# rCSL_dmaxpdsp_001 register map
Vendor: Texas Instruments
Peripheral module from a debugger description file (folder c674x).
Registers are 32-bit, access not given, reset 0x0 unless marked. A register's access mark holds for its fields unless they carry their own. Offsets are as the file gives them; lines under a group give offsets from that group; [hi:lo] are bit positions; {n}, {i} and the like mark numbered series; 'fields as' and 'values as' point back to an identical list; <NAME> marks a mode.

## dMAXPDSP — dMAX Packed Data Structure Processor
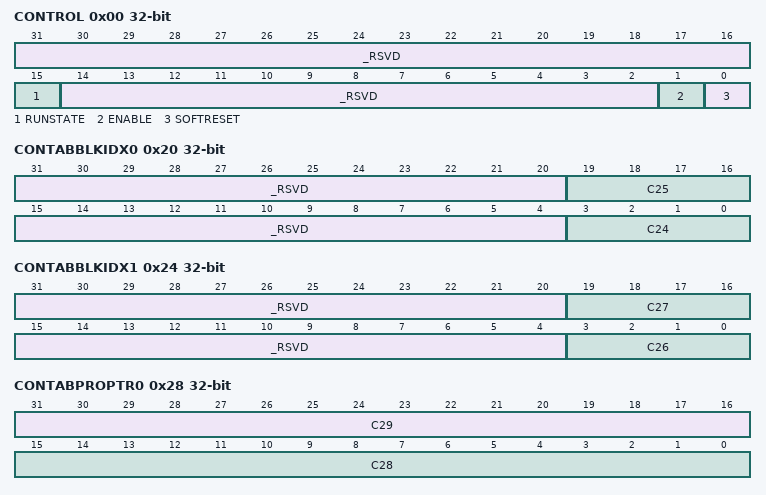
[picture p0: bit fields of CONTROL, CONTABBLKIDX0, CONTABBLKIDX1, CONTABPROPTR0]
0x00 CONTROL
  [31:16] _RSVD — (access N)
  [15] RUNSTATE ro
    0=HALT; 1=RUN
  [14:2] _RSVD — (access N)
  [1] ENABLE rw
    0=DISABLE; 1=ENABLE
  [0] SOFTRESET ro
    0=RESET; 1=OUT_OF_RESET
0x20 CONTABBLKIDX0 — Constant Table Block Index Register 0
  [31:20] _RSVD — (access N)
  [19:16] C25 rw — Constant Table Entry 25 Block Index
  [15:4] _RSVD — (access N)
  [3:0] C24 rw — Constant Table Entry 24 Block Index
0x24 CONTABBLKIDX1 — Constant Table Block Index Register 1
  [31:20] _RSVD — (access N)
  [19:16] C27 rw — Constant Table Entry 27 Block Index
  [15:4] _RSVD — (access N)
  [3:0] C26 rw — Constant Table Entry 26 Block Index
0x28 CONTABPROPTR0 rw — Constant Table Programmable Pointer Register 0
  [31:16] C29 — Constant Table Entry 29 Pointer
  [15:0] C28 — Constant Table Entry 28 Pointer
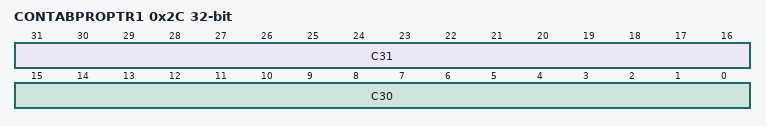
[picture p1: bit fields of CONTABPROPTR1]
0x2C CONTABPROPTR1 rw — Constant Table Programmable Pointer Register 1
  [31:16] C31 — Constant Table Entry 31 Pointer
  [15:0] C30 — Constant Table Entry 30 Pointer
